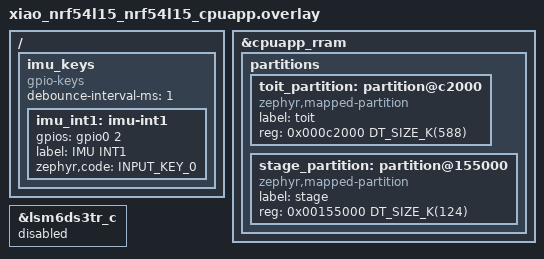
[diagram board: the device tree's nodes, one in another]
#include <zephyr/dt-bindings/input/input-event-codes.h>

/* XIAO nRF54L15 (Zephyr 4.5), no MCUboot: the app is linked at 0x0 and may use
 * the unused mcuboot area and slot0, up to 0xc2000 (CONFIG_FLASH_LOAD_SIZE in the
 * board .conf turns overflow into a link error). Toit's flash registry takes the
 * MCUboot upgrade slot's address, less the agent's staging area at its end;
 * the storage partition after it is left alone for settings. */
/delete-node/ &slot1_partition;

&cpuapp_rram {
	partitions {
		toit_partition: partition@c2000 {
			compatible = "zephyr,mapped-partition";
			label = "toit";
			reg = <0x000c2000 DT_SIZE_K(588)>;
		};

		/* The agent's staging area (zephyr/src/agent/store.c), carved from
		 * the end of the former 712 KB toit partition; same size as the C6's (#51). */
		stage_partition: partition@155000 {
			compatible = "zephyr,mapped-partition";
			label = "stage";
			reg = <0x00155000 DT_SIZE_K(124)>;
		};
	};
};

/* The IMU (LSM6DS3TR-C) is driven from Toit over I2C (ztoit.I2c "i2c30"), so
 * Zephyr's own driver is off and does not claim the chip or its INT1 pin. INT1
 * (P0.02) is a gpio-keys child: ztoit.Key "imu_int1" wakes a Toit task on it. */
&lsm6ds3tr_c {
	status = "disabled";
};

/ {
	imu_keys {
		compatible = "gpio-keys";
		/* The IMU pulses INT1 for a few ms per tap; the 30 ms default
		 * debounce swallows every pulse (ktau journal 03). */
		debounce-interval-ms = <1>;

		imu_int1: imu-int1 {
			gpios = <&gpio0 2 GPIO_ACTIVE_HIGH>;
			label = "IMU INT1";
			zephyr,code = <INPUT_KEY_0>;
		};
	};
};
